VERSION ""

NS_ :

BS_:

BU_: CCU ACU

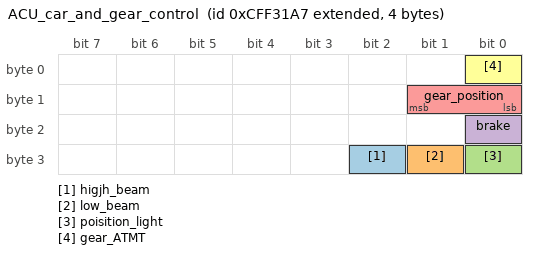
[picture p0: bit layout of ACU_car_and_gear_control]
BO_ 2365534631 ACU_car_and_gear_control: 4 ACU
 SG_ higjh_beam : 26|1@0+ (1,0) [0|0] ""  CCU,ACU
 SG_ low_beam : 25|1@0+ (1,0) [0|0] " bit"  CCU,ACU
 SG_ poisition_light : 24|1@0+ (1,0) [0|0] "bit"  CCU,ACU
 SG_ brake : 16|1@0+ (1,0) [0|1] "bit"  CCU,ACU
 SG_ gear_position : 9|2@0+ (1,0) [0|3] "bit"  CCU,ACU
 SG_ gear_ATMT : 0|1@0+ (1,0) [0|1] "bit"  CCU,ACU

BO_TX_BU_ 2365534631 : CCU,ACU;

BA_DEF_ SG_  "GenSigSendType" ENUM  "Cyclic","OnWrite","OnWriteWithRepetition","OnChange","OnChangeWithRepetition","IfActive","IfActiveWithRepetition","NoSigSendType";
BA_DEF_ BO_  "GenMsgCycleTime" INT 0 0;
BA_DEF_ BO_  "GenMsgSendType" ENUM  "Cyclic","not_used","not_used","not_used","not_used","Cyclic","not_used","IfActive","NoMsgSendType";
BA_DEF_  "DBName" STRING ;
BA_DEF_  "BusType" STRING ;
BA_DEF_DEF_  "GenSigSendType" "Cyclic";
BA_DEF_DEF_  "GenMsgCycleTime" 0;
BA_DEF_DEF_  "GenMsgSendType" "NoMsgSendType";
BA_DEF_DEF_  "DBName" "";
BA_DEF_DEF_  "BusType" "CAN";
BA_ "DBName" "test";
BA_ "GenMsgCycleTime" BO_ 2365534631 100;
